# dbb_rffe register map
Registers are 16-bit, access not given, no defined reset value unless marked. A register's access mark holds for its fields unless they carry their own. Offsets are from the block's base; lines under a group give offsets from that group; [hi:lo] are bit positions; {n}, {i} and the like mark numbered series; 'fields as' and 'values as' point back to an identical list; <NAME> marks a mode.

## Memory map
? dbb_rffe — DIBS RFFE IC Config

## dbb_rffe — DIBS RFFE IC Config
Base ?
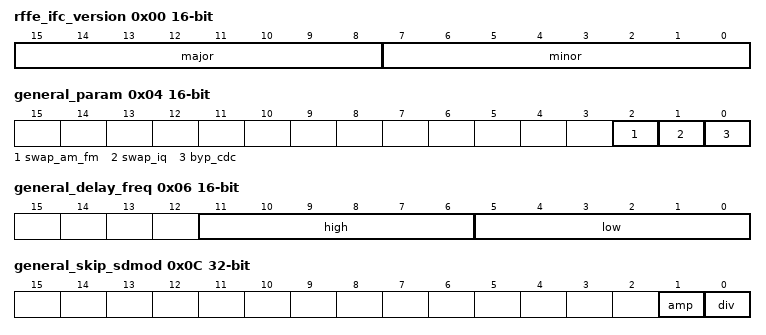
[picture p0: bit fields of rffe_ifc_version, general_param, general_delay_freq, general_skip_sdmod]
0x00 rffe_ifc_version — version
  [15:8] major — version register major
  [7:0] minor — Version register minor
0x02 rffe_ifc_rffe_version — Select the output mode to the RFFE: '00' = PR400 1G RFFE mode, '01' = the PR400 2G RFFE mode, '10' = PAN 1G RFFE mode, '11' = PAN 2G mode
  [1:0] version
    0=PR400_1G; 1=PR400_2G; 2=PAN_1G; 3=PAN_2G
0x04 general_param — param
  [2] swap_am_fm — Swap AM and FM signals
  [1] swap_iq — Swap I and Q signals
  [0] byp_cdc — Bypass the clock domain crossing module
0x06 general_delay_freq — delay_freq
  [11:6] high — Delay of data for frequency DAC
  [5:0] low — Delay of data for programmable frequency divider
0x08 general_delay_amp — Delay of amplitude data
0x0A general_spi_invert_csn — When set to '1', the SPI chip select line is inverted.
0x0C general_skip_sdmod 32-bit — skip_sdmod
  [1] amp — Skip sigma delta modulation of amplitude output.
  [0] div — Skip sigma delta modulation of frequency output for divider.
0x10 tx_seq_ena_seq_lngth_total — The value set the number of commands that are send to the AFE
0x12 tx_seq_ena_seq_lngth_part — The value set the number of commands that are send to the AFE before going into wait mode
{0x14+2i} tx_seq_ena_cmd[{i}] (i=0..15) — AFE enable commands
0x34 tx_seq_dis_seq_lngth_total — The value set the number of commands that are send to the AFE
0x36 tx_seq_dis_seq_lngth_part — The value set the number of commands that are send to the AFE before going into wait mode
{0x38+2i} tx_seq_dis_cmd[{i}] (i=0..15) — AFE disable commands
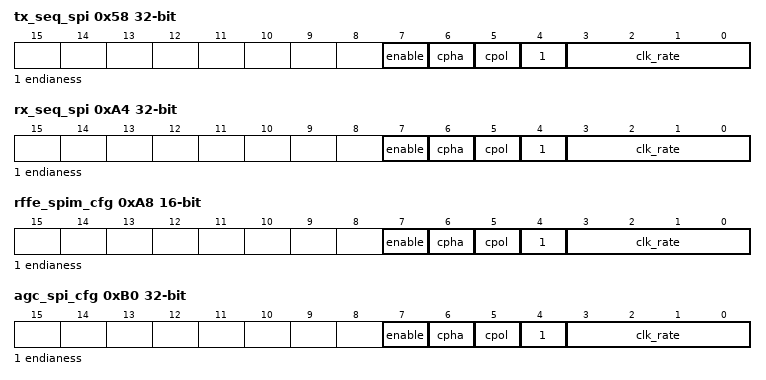
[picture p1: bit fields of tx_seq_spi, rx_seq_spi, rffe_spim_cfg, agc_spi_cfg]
0x58 tx_seq_spi 32-bit — spi
  [7] enable — enables SPI master module when set to '1'
  [6] cpha — When it is set to '0' the data is sampled on the first clock edge; When it is set to '1' the data is sampled on the second clock edge
  [5] cpol — When it is set to '1' The inactive clock is HIGH
  [4] endianess — When it is set to '0' it will send out the data from lsb to msb
  [3:0] clk_rate — The value devides the clock
0x5C rx_seq_ena_seq_lngth_total — The value set the number of commands that are send to the AFE
0x5E rx_seq_ena_seq_lngth_part — The value set the number of commands that are send to the AFE before going into wait mode
{0x60+2i} rx_seq_ena_cmd[{i}] (i=0..15) — AFE enable commands
0x80 rx_seq_dis_seq_lngth_total — The value set the number of commands that are send to the AFE
0x82 rx_seq_dis_seq_lngth_part — The value set the number of commands that are send to the AFE before going into wait mode
{0x84+2i} rx_seq_dis_cmd[{i}] (i=0..15) — AFE disable commands
0xA4 rx_seq_spi 32-bit — spi
  fields as tx_seq_spi
0xA8 rffe_spim_cfg — cfg
  [7] enable — enables SPI master module when set to '1'
  [6] cpha — When it is set to '0' the data is sampled on the first clock edge; When it is set to '1' the data is sampled on the second clock edge
  [5] cpol — When it is set to '1' The inactive clock is HIGH
  [4] endianess — When it is set to '0' it will send out the data from lsb to msb
  [3:0] clk_rate — The value divides the clock
0xAA rffe_spim_data_out — The data to be sent via spi to the AFE.
0xAC rffe_spim_start_transaction — The start pulse to start a new spi transaction.
0xAE rffe_spim_data_in — The data received via spi from the AFE.
0xB0 agc_spi_cfg 32-bit — cfg
  fields as rffe_spim_cfg
0xB4 agc_enc5_gain_addr — The target address for the gain settings to be written to
{0xB6+2i} agc_enc5_gain_table[{i}] (i=0..7) — The settings for the AFE gain register per gain step, format is 4 LPF, MX2, MX1, LNA
{0xC6+2i} agc_enc5_gain_table_db[{i}] (i=0..7) — Setting the AFE gain in db for the RSSI block
0xD6 agc_enc5_ready_tmr — Set the amount of time that it takes to set the AFE front-end gain after a new gain has been written to the FIFO
0xD8 agc_enc5_offs_i_addr — The target address for the dc offset setting for the I branch channel
0xDA agc_enc5_offs_q_addr — The target address for the dc offset setting for the Q branch channel
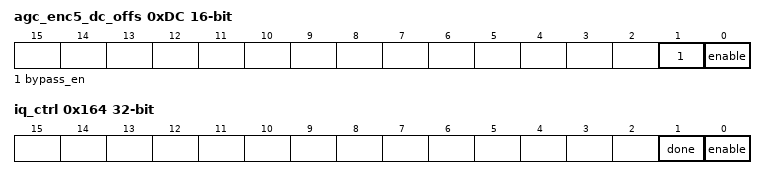
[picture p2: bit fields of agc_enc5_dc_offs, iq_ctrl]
0xDC agc_enc5_dc_offs — dc_offs
  [1] bypass_en — Use the software controled registers offs_*_bypass to set the DC offset values send to the AFE and bypass the values generated by the AGC DC offset algorithm
  [0] enable — If 1 then no DC offset is written when the AGC changes gain setting
{0xDE+2i} agc_enc5_offs_i_bypass[{i}] (i=0..7) — Software diffined offsets per gain step for the I channel
{0xEE+2i} agc_enc5_offs_q_bypass[{i}] (i=0..7) — Software diffined offsets per gain step for the Q channel
{0xFE+2i} agc_enc5_curr_dc_offs_i[{i}] (i=0..7) — Current values of the DC offset algorithm per gain step for the I channel
{0x10E+2i} agc_enc5_curr_dc_offs_q[{i}] (i=0..7) — Current values of the DC offset algorithm per gain step for the Q channel
0x120 general2_skip_fir_amp — skip_amplitude FIR filter
{0x122+2i} general2_fir_coefficients[{i}] (i=0..3) — FIR filter coefficients *signed*
0x12A general2_fir_scalingfactor — FIR filter scalingfactor
0x12C anti_alias_am_skip_fir — Skip anti-alias FIR filter in amplitude path
{0x12E+2i} anti_alias_am_coeff[{i}] (i=0..3) — FIR filter coefficients
0x136 anti_alias_am_scalingfactor — FIR filter scalingfactor
0x138 anti_alias_fm_skip_fir — Skip Anti-alias filter in FM path (for BTLE speed mode)
{0x13A+2i} anti_alias_fm_coeff[{i}] (i=0..3) — FIR filter coefficients (FM path anti-alias filter)
0x142 anti_alias_fm_scalingfactor — FIR filter scalingfactor (FM path anti-alias filter)
0x144 cdc_clk_div_en — Enable CDC clock divide-by-2 to enable DBB@16MHz
0x164 iq_ctrl 32-bit
  [1] done — IQ measurement complete.
  [0] enable — Enable the IQ measurement.
0x168 iq_data
